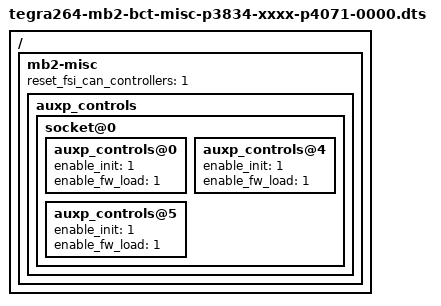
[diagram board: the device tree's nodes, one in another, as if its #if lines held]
/*
 * SPDX-FileCopyrightText: Copyright (c) 2024-2025, NVIDIA CORPORATION & AFFILIATES. All rights reserved.
 * SPDX-License-Identifier: BSD-3-Clause
 *
 * Redistribution and use in source and binary forms, with or without
 * modification, are permitted provided that the following conditions are met:
 *
 * 1. Redistributions of source code must retain the above copyright notice, this
 * list of conditions and the following disclaimer.
 *
 * 2. Redistributions in binary form must reproduce the above copyright notice,
 * this list of conditions and the following disclaimer in the documentation
 * and/or other materials provided with the distribution.
 *
 * 3. Neither the name of the copyright holder nor the names of its
 * contributors may be used to endorse or promote products derived from
 * this software without specific prior written permission.
 *
 * THIS SOFTWARE IS PROVIDED BY THE COPYRIGHT HOLDERS AND CONTRIBUTORS "AS IS"
 * AND ANY EXPRESS OR IMPLIED WARRANTIES, INCLUDING, BUT NOT LIMITED TO, THE
 * IMPLIED WARRANTIES OF MERCHANTABILITY AND FITNESS FOR A PARTICULAR PURPOSE ARE
 * DISCLAIMED. IN NO EVENT SHALL THE COPYRIGHT HOLDER OR CONTRIBUTORS BE LIABLE
 * FOR ANY DIRECT, INDIRECT, INCIDENTAL, SPECIAL, EXEMPLARY, OR CONSEQUENTIAL
 * DAMAGES (INCLUDING, BUT NOT LIMITED TO, PROCUREMENT OF SUBSTITUTE GOODS OR
 * SERVICES; LOSS OF USE, DATA, OR PROFITS; OR BUSINESS INTERRUPTION) HOWEVER
 * CAUSED AND ON ANY THEORY OF LIABILITY, WHETHER IN CONTRACT, STRICT LIABILITY,
 * OR TORT (INCLUDING NEGLIGENCE OR OTHERWISE) ARISING IN ANY WAY OUT OF THE USE
 * OF THIS SOFTWARE, EVEN IF ADVISED OF THE POSSIBILITY OF SUCH DAMAGE.
 */
/*
# CFG Version 1.0
# This File contains the configuration of multiple rails.
*/
/dts-v1/;

#ifdef AUTO_BUILD
#include "tegrabl_carveout_id.h"
#else
#include "t264_tegrabl_carveout_id.h"
#endif

#include "tegra264-mb2-bct-common.dtsi"
/ {
    mb2-misc {
        /*
         * When FSI enable_unhalt= <1>, reset_fsi_can_controllers field will
         * be ignored.
         * When FSI enable_unhalt = <0> and reset_fsi_can_controllers = <1>,
         * FSI CAN will reset
         */
        reset_fsi_can_controllers = <1>;

        auxp_controls {
            socket@0 {
                /* Control fields for AON cluster. */
                auxp_controls@0 {
                    enable_init = <1>;
                    enable_fw_load = <1>;
                };

                /* Control fields for APE cluster. */
                auxp_controls@4 {
                    enable_init = <1>;
                    enable_fw_load = <1>;
                };

                /* Control fields for APE1 cluster. */
                auxp_controls@5 {
                    enable_init = <1>;
                    enable_fw_load = <1>;
                };
            };
        };
    };
};

